# CTRL_MODULE_WKUP register map
Vendor: Texas Instruments
Peripheral module from a debugger description file (folder TDA2Px).
Registers are 32-bit, access per field, reset 0x0 unless marked. A register's access mark holds for its fields unless they carry their own. Offsets are as the file gives them; lines under a group give offsets from that group; [hi:lo] are bit positions; {n}, {i} and the like mark numbered series; 'fields as' and 'values as' point back to an identical list; <NAME> marks a mode.

## CTRL_MODULE_WKUP
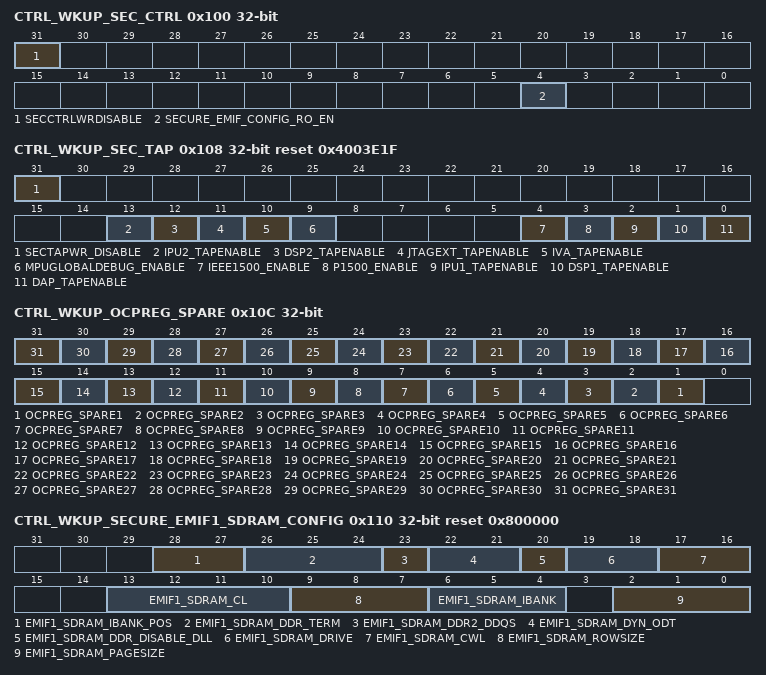
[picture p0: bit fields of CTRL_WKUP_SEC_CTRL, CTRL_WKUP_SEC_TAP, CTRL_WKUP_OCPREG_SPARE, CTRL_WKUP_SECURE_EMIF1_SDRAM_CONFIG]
0x100 CTRL_WKUP_SEC_CTRL — Control Register
  [31] SECCTRLWRDISABLE rw — Control Register write disable control. 0x0 = Write in this register is allowed 0x1 = Write in this register is forbidden
  [4] SECURE_EMIF_CONFIG_RO_EN rw — Access mode for registers: CTRL_WKUP_EMIF1_SDRAM_CONFIG CTRL_WKUP_EMIF2_SDRAM_CONFIG 0x0 = These registers are RW 0x1 = These registers are RO
0x108 CTRL_WKUP_SEC_TAP reset 0x4003E1F — TAP controllers register.
  [31] SECTAPWR_DISABLE rw — TAP controllers register write disable control
  [13] IPU2_TAPENABLE rw — IPU2 TAP control
    0=IPU2_TAP_controller_is_disabled; 1=IPU2_TAP_controller_is_enabled
  [12] DSP2_TAPENABLE rw — DSP2 TAP control
    0=DSP2_TAP_controller_is_disabled; 1=DSP2_TAP_controller_is_enabled
  [11] JTAGEXT_TAPENABLE rw — External JTAG expansion TAP control.
    0=DISABLED (external JTAG TAP controller is disabled); 1=ENABLED (external JTAG TAP controller is enabled)
  [10] IVA_TAPENABLE rw — IVA TAP control
    0=DISABLED (IVA TAP controller is disabled); 1=ENABLED (IVA TAP controller is enabled)
  [9] MPUGLOBALDEBUG_ENABLE rw — MPU TAP control
    0=DISABLED (MPU TAP controller is disabled); 1=ENABLED (MPU TAP controller is enabled)
  [4] IEEE1500_ENABLE rw — IEEE1500 and P1500 access enable
  [3] P1500_ENABLE rw — P1500 access enable
    0=DISABLED (P1500 controller is disabled); 1=ENABLED (P1500 controller is enabled)
  [2] IPU1_TAPENABLE rw — IPU1 TAP control
    0=DISABLED (IPU1 TAP controller is disabled); 1=ENABLED (IPU1 TAP controller is enabled)
  [1] DSP1_TAPENABLE rw — DSP1 TAP control
    0=DISABLED (DSP1 TAP controller is disabled); 1=ENABLED (DSP1 TAP controller is enabled)
  [0] DAP_TAPENABLE rw — DAP TAP control
    0=DISABLED (DAP TAP controller is disabled); 1=ENABLED (DAP TAP controller is enabled)
0x10C CTRL_WKUP_OCPREG_SPARE — OCP Spare Register
  [n] OCPREG_SPARE{n} rw (n=1..31) — OCP spare register {n}
0x110 CTRL_WKUP_SECURE_EMIF1_SDRAM_CONFIG reset 0x800000 — EMIF1 SDRAM configuration register. Its values are exported to EMIF_SDRAM_CONFIG register at POR. For bit field descriptions see EMIF_SDRAM_CONFIG register in, EMIF Controller, in , Memory Subsystem. Write to this register is allowed if the [4] SECURE_EMIF_CONFIG_RO_EN bit is set to 0x0 (default).
  [28:27] EMIF1_SDRAM_IBANK_POS rw — Internal bank position.
  [26:24] EMIF1_SDRAM_DDR_TERM rw — DDR2 and DDR3 termination resistor value.
  [23] EMIF1_SDRAM_DDR2_DDQS rw — DDR2 differential DQS enable.
  [22:21] EMIF1_SDRAM_DYN_ODT rw — DDR3 Dynamic ODT.
  [20] EMIF1_SDRAM_DDR_DISABLE_DLL rw — Disable DLL select.
  [19:18] EMIF1_SDRAM_DRIVE rw — SDRAM drive strength.
  [17:16] EMIF1_SDRAM_CWL rw — DDR3 CAS Write latency.
  [13:10] EMIF1_SDRAM_CL rw — CAS Latency.
  [9:7] EMIF1_SDRAM_ROWSIZE rw — Row Size.
  [6:4] EMIF1_SDRAM_IBANK rw — Internal Bank setup.
  [2:0] EMIF1_SDRAM_PAGESIZE rw — Page Size.
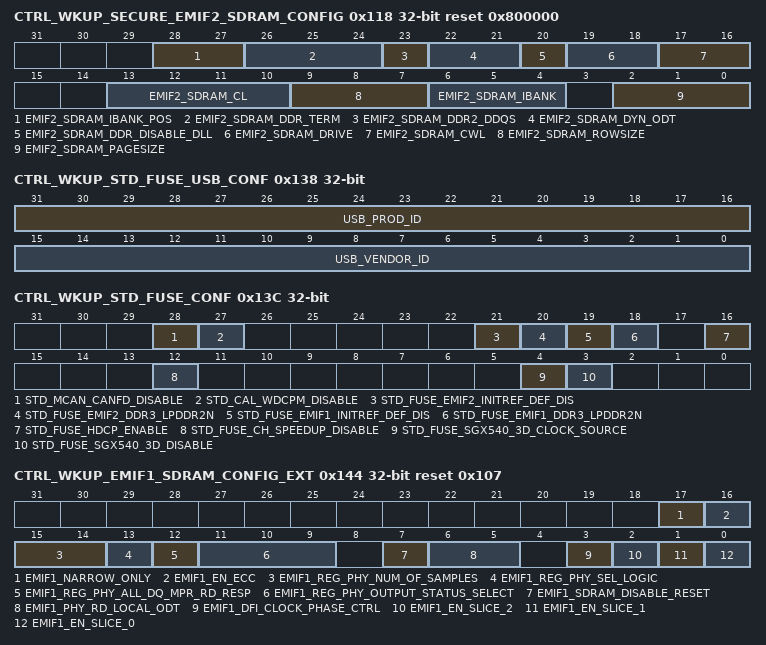
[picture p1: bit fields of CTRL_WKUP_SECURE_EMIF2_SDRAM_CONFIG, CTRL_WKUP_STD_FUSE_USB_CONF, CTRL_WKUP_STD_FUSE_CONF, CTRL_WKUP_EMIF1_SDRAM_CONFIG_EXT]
0x118 CTRL_WKUP_SECURE_EMIF2_SDRAM_CONFIG reset 0x800000 — EMIF2 SDRAM register. Its values are exported to EMIF_SDRAM_CONFIG register at POR. For bit field descriptions see EMIF_SDRAM_CONFIG register in, EMIF Controller, in , Memory Subsystem. Write to this register is allowed if the [4] SECURE_EMIF_CONFIG_RO_EN bit is set to 0x0 (default).
  [28:27] EMIF2_SDRAM_IBANK_POS rw — Internal bank position.
  [26:24] EMIF2_SDRAM_DDR_TERM rw — DDR2 and DDR3 termination resistor value.
  [23] EMIF2_SDRAM_DDR2_DDQS rw — DDR2 differential DQS enable.
  [22:21] EMIF2_SDRAM_DYN_ODT rw — DDR3 Dynamic ODT.
  [20] EMIF2_SDRAM_DDR_DISABLE_DLL rw — Disable DLL select.
  [19:18] EMIF2_SDRAM_DRIVE rw — SDRAM drive strength.
  [17:16] EMIF2_SDRAM_CWL rw — DDR3 CAS Write latency.
  [13:10] EMIF2_SDRAM_CL rw — CAS Latency.
  [9:7] EMIF2_SDRAM_ROWSIZE rw — Row Size.
  [6:4] EMIF2_SDRAM_IBANK rw — Internal Bank setup.
  [2:0] EMIF2_SDRAM_PAGESIZE rw — Page Size.
0x138 CTRL_WKUP_STD_FUSE_USB_CONF ro — Standard Fuse conf [31:0]. Register shows part of the chip eFuse configuration on the OCP interface. Reading at the address of one of these registers provides a direct view into a part of the eFuse chain.
  [31:16] USB_PROD_ID — USB Product Identification
  [15:0] USB_VENDOR_ID — USB Vendor Identification
0x13C CTRL_WKUP_STD_FUSE_CONF ro reset not defined — Standard Fuse conf [63:32]. Register shows part of the chip eFuse configuration on the OCP interface. Reading at the address of one of these registers provides a direct view into a part of the eFuse chain.
  [28] STD_MCAN_CANFD_DISABLE — 0x0 = MCAN CAN FD mode enabled 0x1 = MCAN CAN FD mode disabled
  [27] STD_CAL_WDCPM_DISABLE — 0x0 = WDR DPCM function is enabled 0x1 = WDR DPCM function is disabled
  [21] STD_FUSE_EMIF2_INITREF_DEF_DIS — Disable EMIF2 DDR refresh and initialization sequence 0x1 = refresh and initialization sequence are disabled 0x0 = refresh and initialization sequence are enabled
  [20] STD_FUSE_EMIF2_DDR3_LPDDR2N — EMIF2 DDR3 0x1= DDR3 configured 0x0 = reserved
  [19] STD_FUSE_EMIF1_INITREF_DEF_DIS — Disable EMIF1 DDR refresh and initialization sequence 0x1 = refresh and initialization sequence are disabled 0x0 = refresh and initialization sequence are enabled
  [18] STD_FUSE_EMIF1_DDR3_LPDDR2N — EMIF1 DDR3 0x1 = DDR3 configured 0x0 = reserved
  [16] STD_FUSE_HDCP_ENABLE — Enable HDCP 0x0 = enables HDCP 0x1 = disables HDCP
  [12] STD_FUSE_CH_SPEEDUP_DISABLE — ROM code settings for configuration header block and speedup block. Only SW access (no hardware access). 0x0 = enables CH and speedup 0x1 = disables CH and speedup
  [4] STD_FUSE_SGX540_3D_CLOCK_SOURCE — Functional clock selection for the 3D accelerator engine 0x0 = GPU is fully enabled (DPLL_CORE/PER) 0x1 = GPU is partially enabled (DPLL_PER/8 max)
  [3] STD_FUSE_SGX540_3D_DISABLE — Disable the 3D accelerator engine 0x1 = SGX is disabled 0x0 = SGX is enabled
0x144 CTRL_WKUP_EMIF1_SDRAM_CONFIG_EXT reset 0x107 — SLICE register for emif1 and emif2
  [17] EMIF1_NARROW_ONLY rw — EMIF1 operates in narrow mode, to allow for data macros to be powered down to save power 0x0 = narrow mode disabled 0x1 = narrow mode enabled
  [16] EMIF1_EN_ECC rw — EMIF1 ECC enable 0x0 = ECC is disabled 0x1 = ECC is enabled
  [15:14] EMIF1_REG_PHY_NUM_OF_SAMPLES rw — Controls the number of DQ samples required for read leveling. The recommended setting for full leveling is 0x3 (128 samples) and for incremental leveling is 0x0 (4 samples). 0x0 = 4 samples 0x1 = 8 samples. 0x2 = 16 samples 0x3 = 128 samples
  [13] EMIF1_REG_PHY_SEL_LOGIC rw — Selects an algorithm for read leveling. The use of algorithm 1 (set by default) is recommended. 0x0 = Algorithm 1 is used 0x1 = Algorithm 2 is used
  [12] EMIF1_REG_PHY_ALL_DQ_MPR_RD_RESP rw — Analysis method of DQ bits during read leveling. 0x0: if the DRAM provides a read response on only one DQ bit (this can be any bit, since in this mode all 8 DQ bits are OR-ed together). This is the default setting and works with all memory types (memories send responses on all DQ bits or on a single DQ bit). 0x1: if the DRAM provides a read response on all DQ bits.
  [11:9] EMIF1_REG_PHY_OUTPUT_STATUS_SELECT rw — Selects the status to be observed on the outputs of the DDR PHYs through 0x0 = selects phy_reg_rdlvl_start_ratio[7:0] 0x1 = selects phy_reg_rdlvl_start_ratio[15:8] 0x2 = selects phy_reg_rdlvl_end_ratio[7:0] 0x3 = selects phy_reg_rdlvl_end_ratio[15:8]
  [7] EMIF1_SDRAM_DISABLE_RESET rw — DDR3 SDRAM reset disable. 0x0 = DDR3 SDRAM reset signal is enabled. It can be asserted by EMIF 0x1 = DDR3 SDRAM reset signal is disabled. It is forbidden to EMIF to assert it.
  [6:5] EMIF1_PHY_RD_LOCAL_ODT rw — Control of ODT (on – die termination) settings for the device DDR I/Os. ODT is enabled only during read operations when termination is required. 0x0 = ODT disabled 0x1= 60 Ohms 0x2 = 80 Ohms 0x3 =120 Ohms
  [3] EMIF1_DFI_CLOCK_PHASE_CTRL rw — EMIF_FICLK clock phase control (shifting by 180°). For normal operation this bit must always be set to 0x0 (disabled).
  [2] EMIF1_EN_SLICE_2 rw — Enable command PHY 2. When using DDR3 this bit can be set to 0x0 or 0x1. For lower power consumption 0x0 is used.
  [1] EMIF1_EN_SLICE_1 rw — Enable command PHY 1. 0x1 is the mandatory setting if DDR3 is used. EMIF1_EN_SLICE_0 and EMIF1_EN_SLICE_1 have to be programmed with the same value.
  [0] EMIF1_EN_SLICE_0 rw — Enable command PHY 0. 0x1 is the mandatory setting if DDR3 is used. EMIF1_EN_SLICE_0 and EMIF1_EN_SLICE_1 have to be programmed with the same value.
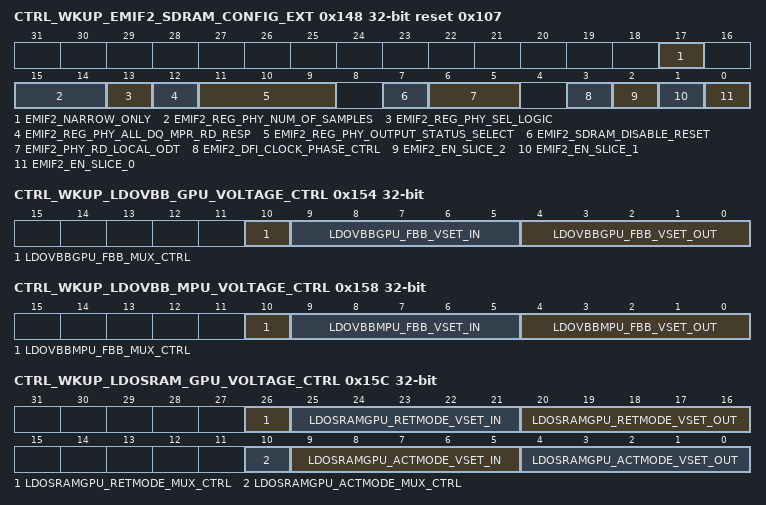
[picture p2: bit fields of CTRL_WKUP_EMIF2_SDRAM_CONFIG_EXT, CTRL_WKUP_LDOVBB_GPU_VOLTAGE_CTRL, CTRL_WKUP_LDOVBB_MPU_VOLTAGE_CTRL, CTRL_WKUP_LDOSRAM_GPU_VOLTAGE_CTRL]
0x148 CTRL_WKUP_EMIF2_SDRAM_CONFIG_EXT reset 0x107 — SLICE register for emif1 and emif2
  [17] EMIF2_NARROW_ONLY rw — EMIF2 operates in narrow mode, to allow for data macros to be powered down to save power 0x0 = narrow mode disabled 0x1 = narrow mode enabled
  [15:14] EMIF2_REG_PHY_NUM_OF_SAMPLES rw — Controls the number of DQ samples required for read leveling. The recommended setting for full leveling is 0x3 (128 samples) and for incremental leveling is 0x0 (4 samples). 0x0 = 4 samples 0x1 = 8 samples. 0x2 = 16 samples 0x3 = 128 samples
  [13] EMIF2_REG_PHY_SEL_LOGIC rw — Selects an algorithm for read leveling. The use of algorithm 1 (set by default) is recommended. 0x0 = Algorithm 1 is used 0x1 = Algorithm 2 is used
  [12] EMIF2_REG_PHY_ALL_DQ_MPR_RD_RESP rw — Analysis method of DQ bits during read leveling. 0x0: if the DRAM provides a read response on only one DQ bit (this can be any bit, since in this mode all 8 DQ bits are OR-ed together). This is the default setting and works with all memory types (memories send responses on all DQ bits or on a single DQ bit). 0x1: if the DRAM provides a read response on all DQ bits.
  [11:9] EMIF2_REG_PHY_OUTPUT_STATUS_SELECT rw — Selects the status to be observed on the outputs of the DDR PHYs through 0x0 = selects phy_reg_rdlvl_start_ratio[7:0] 0x1 = selects phy_reg_rdlvl_start_ratio[15:8] 0x2 = selects phy_reg_rdlvl_end_ratio[7:0] 0x3 = selects phy_reg_rdlvl_end_ratio[15:8]
  [7] EMIF2_SDRAM_DISABLE_RESET rw — DDR3 SDRAM reset disable. 0x0 = DDR3 SDRAM reset signal is enabled. It can be asserted by EMIF 0x1 = DDR3 SDRAM reset signal is disabled. It is forbidden to EMIF to assert it.
  [6:5] EMIF2_PHY_RD_LOCAL_ODT rw — Control of ODT (on – die termination) settings for the device DDR I/Os. ODT is enabled only during read operations when termination is required. 0x0 = ODT disabled 0x1= 60 Ohms 0x2 = 80 Ohms 0x3 =120 Ohms
  [3] EMIF2_DFI_CLOCK_PHASE_CTRL rw — EMIF_FICLK clock phase control (shifting by 180°). For normal operation this bit must always be set to 0x0 (disabled).
  [2] EMIF2_EN_SLICE_2 rw — Enable command PHY 2. When using DDR3 this bit can be set to 0x0 or 0x1. For lower power consumption 0x0 is used.
  [1] EMIF2_EN_SLICE_1 rw — Enable command PHY 1. 0x1 is the mandatory setting if DDR3 is used. EMIF2_EN_SLICE_0 and EMIF2_EN_SLICE_1 have to be programmed with the same value.
  [0] EMIF2_EN_SLICE_0 rw — Enable command PHY 0. 0x1 is the mandatory setting if DDR3 is used. EMIF2_EN_SLICE_0 and EMIF2_EN_SLICE_1 have to be programmed with the same value.
0x14C CTRL_WKUP_EMIF1_SDRAM_CONFIG_EXT_1 ro
  [31:0] EMIF1_PHY_REG_READ_DATA_EYE_LVL
0x150 CTRL_WKUP_EMIF2_SDRAM_CONFIG_EXT_2 ro
  [31:0] EMIF2_PHY_REG_READ_DATA_EYE_LVL
0x154 CTRL_WKUP_LDOVBB_GPU_VOLTAGE_CTRL — GPU Voltage Body Bias LDO Control register
  [10] LDOVBBGPU_FBB_MUX_CTRL rw — Override control of EFUSE Forward Body Bias voltage value 0x0 = efuse value is used 0x1 = override value is used
  [9:5] LDOVBBGPU_FBB_VSET_IN ro — EFUSE Forward Body Bias voltage value
  [4:0] LDOVBBGPU_FBB_VSET_OUT rw — Override value for Forward Body Bias voltage. If ABB is used, depending on the OPP this bit field should be loaded with a value read from one of the CTRL_CORE_STD_FUSE_OPP_VMIN_GPU_x[24:20] VSETABB bit fields. This value applies if LDOVBBGPU_FBB_MUX_CTRL is set to 0x1.
0x158 CTRL_WKUP_LDOVBB_MPU_VOLTAGE_CTRL — MPU Voltage Body Bias LDO Control register
  [10] LDOVBBMPU_FBB_MUX_CTRL rw — Override control of EFUSE Forward Body Bias voltage value 0x0 = efuse value is used 0x1 = override value is used
  [9:5] LDOVBBMPU_FBB_VSET_IN ro — EFUSE Forward Body Bias voltage value
  [4:0] LDOVBBMPU_FBB_VSET_OUT rw — Override value for Forward Body Bias voltage. If ABB is used, depending on the OPP this bit field should be loaded with a value read from one of the CTRL_CORE_STD_FUSE_OPP_VMIN_MPU_x[24:20] VSETABB bit fields. This value applies if LDOVBBMPU_FBB_MUX_CTRL is set to 0x1.
0x15C CTRL_WKUP_LDOSRAM_GPU_VOLTAGE_CTRL — GPU SRAM LDO Control register
  [26] LDOSRAMGPU_RETMODE_MUX_CTRL rw — Override control of EFUSE Retention Mode Voltage value
    0=EFUSE (eFuse value is used); 1=OCP (Override value is used)
  [25:21] LDOSRAMGPU_RETMODE_VSET_IN ro — EFUSE Retention Mode Voltage value (vset[9:5])
  [20:16] LDOSRAMGPU_RETMODE_VSET_OUT rw — Override value for Retention Mode Voltage
  [10] LDOSRAMGPU_ACTMODE_MUX_CTRL rw — Override control of EFUSE Active Mode Voltage value
    values as LDOSRAMGPU_RETMODE_MUX_CTRL
  [9:5] LDOSRAMGPU_ACTMODE_VSET_IN ro — EFUSE Active Mode Voltage value (vset[4:0])
  [4:0] LDOSRAMGPU_ACTMODE_VSET_OUT rw — Override value for Active Mode Voltage value
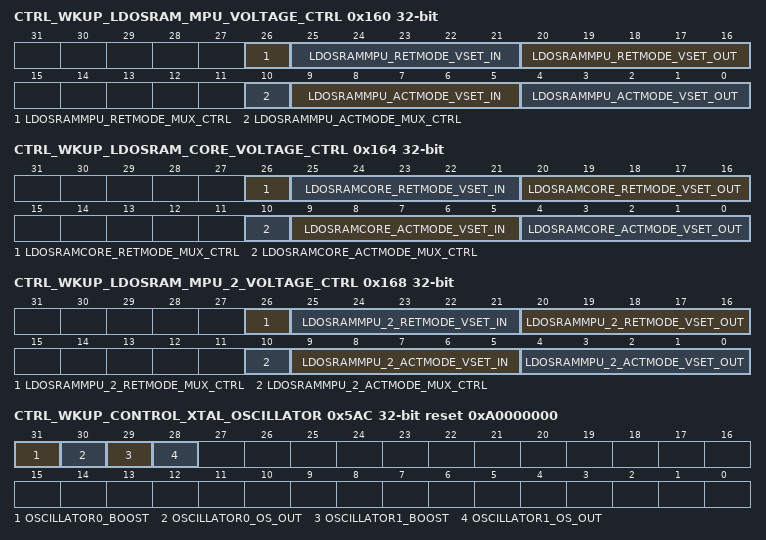
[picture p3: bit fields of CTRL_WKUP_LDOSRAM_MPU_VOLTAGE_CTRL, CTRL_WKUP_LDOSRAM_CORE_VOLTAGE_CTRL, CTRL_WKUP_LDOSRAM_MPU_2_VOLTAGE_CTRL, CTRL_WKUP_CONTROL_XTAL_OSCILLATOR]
0x160 CTRL_WKUP_LDOSRAM_MPU_VOLTAGE_CTRL — MPU SRAM LDO Control register
  [26] LDOSRAMMPU_RETMODE_MUX_CTRL rw — Override control of EFUSE Retention Mode Voltage value
    values as CTRL_WKUP_LDOSRAM_GPU_VOLTAGE_CTRL.LDOSRAMGPU_RETMODE_MUX_CTRL
  [25:21] LDOSRAMMPU_RETMODE_VSET_IN ro — EFUSE Retention Mode Voltage value (vset[9:5])
  [20:16] LDOSRAMMPU_RETMODE_VSET_OUT rw — Override value for Retention Mode Voltage
  [10] LDOSRAMMPU_ACTMODE_MUX_CTRL rw — Override control of EFUSE Active Mode Voltage value
    values as CTRL_WKUP_LDOSRAM_GPU_VOLTAGE_CTRL.LDOSRAMGPU_RETMODE_MUX_CTRL
  [9:5] LDOSRAMMPU_ACTMODE_VSET_IN ro — EFUSE Active Mode Voltage value (vset[4:0])
  [4:0] LDOSRAMMPU_ACTMODE_VSET_OUT rw — Override value for Active Mode Voltage value
0x164 CTRL_WKUP_LDOSRAM_CORE_VOLTAGE_CTRL — Core SRAM LDO Control register
  [26] LDOSRAMCORE_RETMODE_MUX_CTRL rw — Override control of EFUSE Retention Mode Voltage value
    values as CTRL_WKUP_LDOSRAM_GPU_VOLTAGE_CTRL.LDOSRAMGPU_RETMODE_MUX_CTRL
  [25:21] LDOSRAMCORE_RETMODE_VSET_IN ro — EFUSE Retention Mode Voltage value (vset[9:5])
  [20:16] LDOSRAMCORE_RETMODE_VSET_OUT rw — Override value for Retention Mode Voltage
  [10] LDOSRAMCORE_ACTMODE_MUX_CTRL rw — Override control of EFUSE Active Mode Voltage value
    values as CTRL_WKUP_LDOSRAM_GPU_VOLTAGE_CTRL.LDOSRAMGPU_RETMODE_MUX_CTRL
  [9:5] LDOSRAMCORE_ACTMODE_VSET_IN ro — EFUSE Active Mode Voltage value (vset[4:0])
  [4:0] LDOSRAMCORE_ACTMODE_VSET_OUT rw — Override value for Active Mode Voltage value
0x168 CTRL_WKUP_LDOSRAM_MPU_2_VOLTAGE_CTRL — MPU 2nd SRAM LDO Control register
  [26] LDOSRAMMPU_2_RETMODE_MUX_CTRL rw — Override control of EFUSE Retention Mode Voltage value
    values as CTRL_WKUP_LDOSRAM_GPU_VOLTAGE_CTRL.LDOSRAMGPU_RETMODE_MUX_CTRL
  [25:21] LDOSRAMMPU_2_RETMODE_VSET_IN ro — EFUSE Retention Mode Voltage value (vset[9:5])
  [20:16] LDOSRAMMPU_2_RETMODE_VSET_OUT rw — Override value for Retention Mode Voltage
  [10] LDOSRAMMPU_2_ACTMODE_MUX_CTRL rw — Override control of EFUSE Active Mode Voltage value
    values as CTRL_WKUP_LDOSRAM_GPU_VOLTAGE_CTRL.LDOSRAMGPU_RETMODE_MUX_CTRL
  [9:5] LDOSRAMMPU_2_ACTMODE_VSET_IN ro — EFUSE Active Mode Voltage value (vset[4:0])
  [4:0] LDOSRAMMPU_2_ACTMODE_VSET_OUT rw — Override value for Active Mode Voltage value
0x200 CTRL_WKUP_STD_FUSE_DIE_ID_0 ro — Die ID Register : Part 0. Register shows part of the chip eFuse configuration on the OCP interface. Reading at the address of one of these registers provides a direct view into a part of the eFuse chain.
  [31:0] STD_FUSE_DIE_ID_0
0x204 CTRL_WKUP_ID_CODE ro — ID_CODE Key Register
  [31:0] STD_FUSE_IDCODE
{0x204+4i} CTRL_WKUP_STD_FUSE_DIE_ID_{i} ro (i=1..3) — Die ID Register : Part {i}. Register shows part of the chip eFuse configuration on the OCP interface. Reading at the address of one of these registers provides a direct view into a part of the eFuse chain.
  [31:0] STD_FUSE_DIE_ID_{i}
0x214 CTRL_WKUP_STD_FUSE_PROD_ID_0 ro — Prod ID Register : Part 0. Register shows part of the chip eFuse configuration on the OCP interface. Reading at the address of one of these registers provides a direct view into a part of the eFuse chain.
  [31:0] STD_FUSE_PROD_ID
0x5AC CTRL_WKUP_CONTROL_XTAL_OSCILLATOR reset 0xA0000000 — XTAL OSCILLATOR control
  [31] OSCILLATOR0_BOOST rw — Fast startup control of OSC0 0x0 = Fast startup is disabled 0x1 = Fast startup is enabled
  [30] OSCILLATOR0_OS_OUT ro — Oscillator output of OSC0 0x0 = low to high transition in BOOST mode 0x1 = BOOST is disabled
  [29] OSCILLATOR1_BOOST rw — Fast startup control of OSC1 0x0 = Fast startup is disabled 0x1 = Fast startup is enabled
  [28] OSCILLATOR1_OS_OUT ro — Oscillator output of OSC1 0x0 = low to high transition in BOOST mode 0x1 = BOOST is disabled
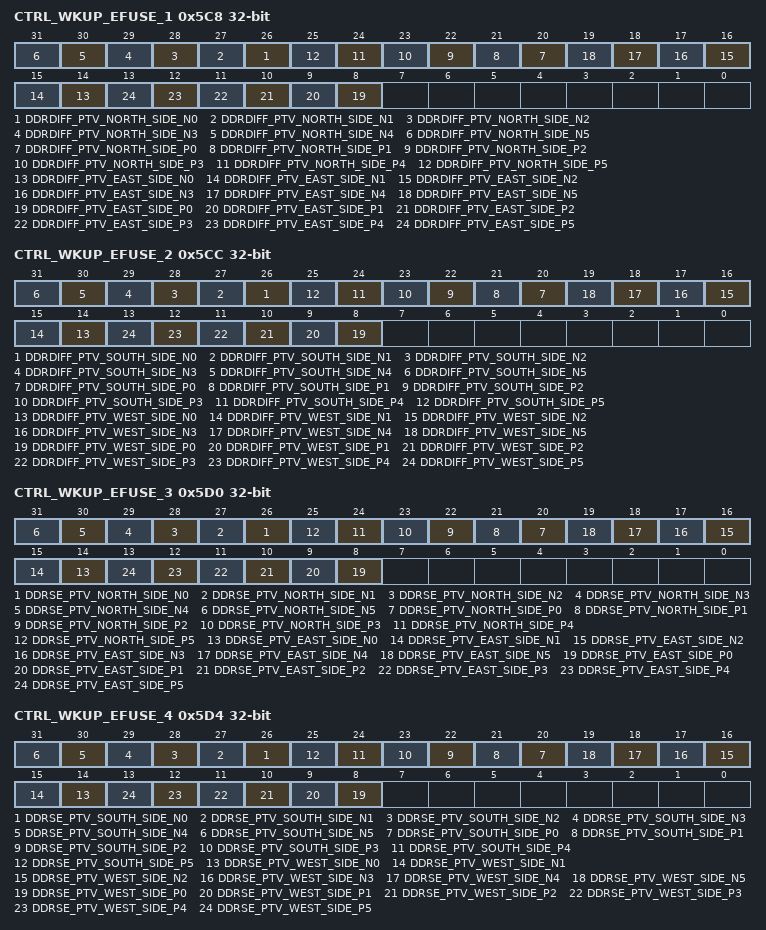
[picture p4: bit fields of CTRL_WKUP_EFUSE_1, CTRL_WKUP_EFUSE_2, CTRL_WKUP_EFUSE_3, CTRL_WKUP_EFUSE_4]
0x5C8 CTRL_WKUP_EFUSE_1 — EFUSE compensation 1
  [n+26] DDRDIFF_PTV_NORTH_SIDE_N{n} rw (n=0..5), [n+20] DDRDIFF_PTV_NORTH_SIDE_P{n} rw (n=0..5), [n+14] DDRDIFF_PTV_EAST_SIDE_N{n} rw (n=0..5), [n+8] DDRDIFF_PTV_EAST_SIDE_P{n} rw (n=0..5)
0x5CC CTRL_WKUP_EFUSE_2 — EFUSE compensation 2
  [n+26] DDRDIFF_PTV_SOUTH_SIDE_N{n} rw (n=0..5), [n+20] DDRDIFF_PTV_SOUTH_SIDE_P{n} rw (n=0..5), [n+14] DDRDIFF_PTV_WEST_SIDE_N{n} rw (n=0..5), [n+8] DDRDIFF_PTV_WEST_SIDE_P{n} rw (n=0..5)
0x5D0 CTRL_WKUP_EFUSE_3 — EFUSE compensation 3
  [n+26] DDRSE_PTV_NORTH_SIDE_N{n} rw (n=0..5), [n+20] DDRSE_PTV_NORTH_SIDE_P{n} rw (n=0..5), [n+14] DDRSE_PTV_EAST_SIDE_N{n} rw (n=0..5), [n+8] DDRSE_PTV_EAST_SIDE_P{n} rw (n=0..5)
0x5D4 CTRL_WKUP_EFUSE_4 — EFUSE compensation 4
  [n+26] DDRSE_PTV_SOUTH_SIDE_N{n} rw (n=0..5), [n+20] DDRSE_PTV_SOUTH_SIDE_P{n} rw (n=0..5), [n+14] DDRSE_PTV_WEST_SIDE_N{n} rw (n=0..5), [n+8] DDRSE_PTV_WEST_SIDE_P{n} rw (n=0..5)
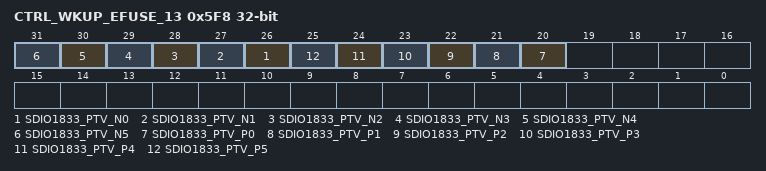
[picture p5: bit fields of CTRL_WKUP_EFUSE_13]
0x5F8 CTRL_WKUP_EFUSE_13
  [n+26] SDIO1833_PTV_N{n} rw (n=0..5), [n+20] SDIO1833_PTV_P{n} rw (n=0..5)
